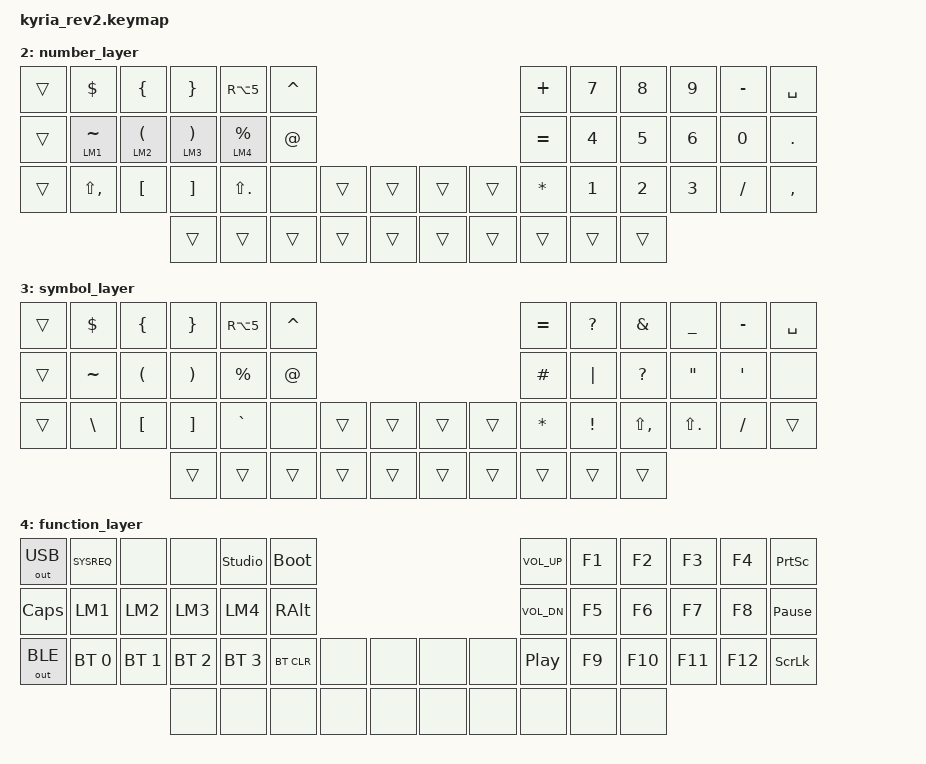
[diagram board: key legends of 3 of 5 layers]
/*
 * Copyright (c) 2020 The ZMK Contributors
 *
 * SPDX-License-Identifier: MIT
 */

#include <behaviors.dtsi>
#include <dt-bindings/zmk/keys.h>
#include <dt-bindings/zmk/bt.h>
#include <dt-bindings/zmk/outputs.h>

#include "lib/keys_os_colemak.h"
#include "lib/base.h"

//	---------------------------------------------------------------------------------------------------------------------------------
//	| 0   | 1   | 2   | 3   | 4   | 5   |                             | 6   | 7   | 8   | 9   | 10  | 11  |
//	| 12  | 13  | 14  | 15  | 16  | 17  |                             | 18  | 19  | 20  | 21  | 22  | 23  |
//	| 24  | 25  | 26  | 27  | 28  | 29  | 30  | 31  |     | 32  | 33  | 34  | 35  | 36  | 37  | 38  | 39  |
//	                  | 40  | 41  | 42  | 43  | 44  |     | 45  | 46  | 47  | 48  | 49  
#define KEYS_L 0 1 2 3 4 5    12 13 14 15 16 17  24 25 26 27 28 29
#define KEYS_R 6 7 8 9 10 11  18 19 20 21 22 23  34 35 36 37 38 39
#define KEYS_T 30 31  32 33   40 41 42 43 44     45 46 47 48 49

#define DEF 0
#define NAV 1
#define NUM 2
#define SYM 3
#define FUN 4
//#define ONE 5
//#define ON2 6

#define X_UNDO LC(Z)
#define X_REDO LC(LS(Z))
#define X_PASTE LC(V)
#define X_COPY LC(C)
#define X_CUT LC(X)

//#define COMBO_ALL(NAME, BINDINGS, KEYPOS) \
//  combo_##NAME { \
//    timeout-ms = <15>; \
//    bindings = <BINDINGS>; \
//    key-positions = <KEYPOS>; \
//  }
//
//#define COMBO_LAYER0(NAME, BINDINGS, KEYPOS) \
//  combo_##NAME { \
//    timeout-ms = <15>; \
//    bindings = <BINDINGS>; \
//    key-positions = <KEYPOS>; \
//    layers = <0>; \
//  }

/ {
	//behaviors {
	//	dk: double-key {
	//		compatible = "zmk,behavior-hold-tap";
	//		label = "DOUBLE_KEY";
	//		#binding-cells = <2>;
	//		flavor = "tap-preferred";
	//		tapping-term-ms = <200>;
	//		quick-tap-ms = <100>;
	//		#global-quick-tap;
	//		bindings = <&kp>, <&kp>;
	//	};
	//	hm: homerow_mods {
	//		compatible = "zmk,behavior-hold-tap";
	//		label = "HOMEROW_MODS";
	//		#binding-cells = <2>;
	//		flavor = "tap-preferred";
	//		tapping-term-ms = <150>;
	//		quick_tap_ms = <150>;
	//		bindings = <&kp>, <&kp>;
	//	};
	//	lm: left_hand_positional_hold_tap {
	//		compatible = "zmk,behavior-hold-tap";
	//		label = "LEFT_HOMEROW_MODS";
	//		#binding-cells = <2>;
	//		flavor = "tap-unless-interrupted";
	//		tapping-term-ms = <100>;
	//		quick-tap-ms = <200>;
	//		bindings = <&kp>, <&kp>;
	//		hold-trigger-key-positions = <6 7 8 9 10 11  18 19 20 21 22 23  34 35 36 37 38 39>;
	//	};
	//	rm: right_hand_positional_hold_tap {
	//		compatible = "zmk,behavior-hold-tap";
	//		label = "RIGHT_HOMEROW_MODS";
	//		#binding-cells = <2>;
	//		flavor = "tap-unless-interrupted";
	//		tapping-term-ms = <100>;
	//		quick-tap-ms = <200>;
	//		bindings = <&kp>, <&kp>;
	//		hold-trigger-key-positions = <0 1 2 3 4 5  12 13 14 15 16 17  24 25 26 27 28 29>;
	//	};
	//};

	macros {
		#include "lib/macros.dtsi"
	};

	behaviors {
		#include "lib/behaviors.dtsi"
	};

//	---------------------------------------------------------------------------------------------------------------------------------
//	| 0   | 1   | 2   | 3   | 4   | 5   |                             | 6   | 7   | 8   | 9   | 10  | 11  |
//	| 12  | 13  | 14  | 15  | 16  | 17  |                             | 18  | 19  | 20  | 21  | 22  | 23  |
//	| 24  | 25  | 26  | 27  | 28  | 29  | 30  | 31  |     | 32  | 33  | 34  | 35  | 36  | 37  | 38  | 39  |
//	                  | 40  | 41  | 42  | 43  | 44  |     | 45  | 46  | 47  | 48  | 49  

//	combos {
//		compatible = "zmk,combos";
//
//		COMBO_ALL(esc, &kp ESC, 1 2);
//		COMBO_ALL(tab, &kp TAB, 9 10);
//		COMBO_ALL(enter, &kp ENTER, 37 38);
//		COMBO_ALL(bspc, &kp BSPC, 13 14);
//
//		COMBO_ALL(l_ctrl_tab, &kp LC(TAB), 44 0);
//		COMBO_ALL(l_ctrl_shift_tab, &kp LC(LC(TAB)), 44 12);
//
//		COMBO_ALL(l_one, &tog ONE, 43 44);
//
//		//COMBO_LAYER0(lctrl, &sk LCTRL, 27 28);
//		COMBO_LAYER0(lalt, &sk LALT, 26 28);
//		COMBO_LAYER0(lgui, &sk LGUI, 25 28);
//		//COMBO_LAYER0(rctrl, &sk RCTRL, 35 36);
//		COMBO_LAYER0(rlalt, &sk LALT, 35 37);
//		COMBO_LAYER0(rgui, &sk RGUI, 35 38);
//
//		COMBO_LAYER0(caps_word_l, &caps_word, 27 28);
//		COMBO_LAYER0(caps_word_r, &caps_word, 37 38);
//	};

	//conditional_layers {
	//	compatible = "zmk,conditional-layers";
	//	tri_layer {
	//		if-layers = <SYM NUM>;
	//		then-layer = <FUN>;
	//	};
	//};

	keymap {
		compatible = "zmk,keymap";

		//  Colemak on OS side
		default_layer {
			//	---------------------------------------------------------------------------------------------------------------------------------
			//	| ??? | Q   | W   | E   | R   | T   |                             | Y   | U   | I   | O   | P   | ??? |
			//	| ??? | A   | S   | D   | F   | G   |                             | H   | J   | K   | L   | ;   | '   |
			//	| ??? | Z   | X   | C   | V   | B   | ??? | ??? |     | ??? | ??? | N   | M   | ,   | .   | /   | ??? |
			//	                  | ??? | ??? | ??? | ??? | ??? |     | ??? | ??? | ??? | ??? | ??? |
			bindings = <
&kp TAB       &kp OC_Q     &kp OC_W     &kp OC_F      &kp OC_P     &kp OC_G                            ___                 &kp OC_J      &kp OC_L     &kp OC_U     &kp OC_Y     &kp OC_AU    &kp OC_OU
&kp BSPC      &ml LM1 OC_A &ml LM2 OC_R &ml LM3 OC_S  &ml LM4 OC_T &ml RALT OC_D                       ___                 &mr RALT OC_H &mr RM1 OC_N &mr RM2 OC_E &mr RM3 OC_I &mr RM4 OC_O &kp SQT
&mt LSHFT ESC &kp OC_Z     &kp OC_X     &kp OC_C      &kp OC_V     &kp OC_B      &none         &none   ___ &none   &none   &kp OC_K      &kp OC_M     &kp COMMA    &kp DOT      &lt NAV FSLH &mt RSHFT RET
                                        &none         &kp RET      &mo FUN       &lt NAV SPACE &mo SYM ___ &mo NAV &mo SYM &mo FUN       &kp SPACE    &none
			>;
		};

		navigation_layer {
			bindings = <
&trans  &kp FSLH  &kp SPACE &kp HASH  &kp SPACE &kp F4                     ___               &kp INS   &kp PG_UP  &kp UP    &kp PG_DN &kp INS   &kp ESC
&trans  &kp LM1   &kp LM2   &kp LM3   &kp LM4   &ml RALT DEL               ___               &kp BSPC  &kp LEFT   &kp DOWN  &kp RIGHT &kp SPACE &kp DEL
&trans  &kp LC(Z) &kp LC(X) &kp LC(C) &kp LC(V) &kp X_PASTE  &none  &none  ___ &none  &none  &none     &kp HOME      &none      &kp END    &kp FSLH  &trans
                            &trans    &trans    &trans       &trans &trans ___ &trans &trans &trans    &trans     &trans
			>;
		};

		number_layer {
			//	---------------------------------------------------------------------------------------------------------------------------------
			//	|     | $   | {   | }   | €   | ^   |                             | -   | 7   | 8   | 9   | +   | /s  |
			//	|     | ~ X | ( X | ) X | % X | @   |                             | =   | 4   | 5   | 6   | 0   | .   |
			//	|     | <   | [   | ]   | >   |     | --- | --- |     | --- | --- | *   | 1   | 2   | 3   | /   | ,   |
			//	                  | --- | --- | --- | --- | --- |     | --- | --- | --- | --- | --- |
			bindings = <
&trans  &kp DLLR       &kp LBRC      &kp RBRC      &kp RA(N5)    &kp CARET                                &kp PLUS  &kp N7  &kp N8  &kp N9  &kp MINUS &kp SPACE
&trans  &mt LM1 TILDE  &mt LM2 LPAR  &mt LM3 RPAR  &mt LM4 PRCNT &kp AT                                   &kp EQUAL &kp N4  &kp N5  &kp N6  &kp N0    &kp DOT
&trans  &kp LS(COMMA)  &kp LBKT      &kp RBKT      &kp LS(DOT)   &none      &trans &trans   &trans &trans &kp STAR  &kp N1  &kp N2  &kp N3  &kp FSLH  &kp COMMA
   									 &trans        &trans        &trans     &trans &trans   &trans &trans &trans    &trans  &trans
			>;
		};

		symbol_layer {
			//	---------------------------------------------------------------------------------------------------------------------------------
			//	|     | $   | {   | }   | €   | ^   |                             | =   | ?   | &   | _   | -   |     |
			//	|     | ~   | (   | )   | %   | @   |                             | *   | |   | '   | "   | '   |     |
			//	|     | \   | [   | ]   | `   |     | --- | --- |     | --- | --- | #   | !   | <   | >   | /   |     |
			//	                  | --- | --- | --- | --- | --- |     | --- | --- | --- | --- | --- |
			bindings = <
&trans  &kp DLLR  &kp LBRC  &kp RBRC  &kp RA(N5) &kp CARET                                &kp EQUAL &kp QMARK &kp AMPS      &kp UNDER   &kp MINUS &kp SPACE
&trans  &kp TILDE &kp LPAR  &kp RPAR  &kp PRCNT  &kp AT                                   &kp HASH  &kp PIPE  &kp QMARK     &kp DQT     &kp SQT   &none
&trans  &kp BSLH  &kp LBKT  &kp RBKT  &kp GRAVE  &none      &trans &trans   &trans &trans &kp STAR  &kp EXCL  &kp LS(COMMA) &kp LS(DOT) &kp FSLH  &trans
                            &trans    &trans     &trans     &trans &trans   &trans &trans &trans    &trans    &trans
			>;
		};

		function_layer {
			bindings = <
&out OUT_USB &kp SYSREQ   &none        &none        &studio_unlock &bootloader                           &kp C_VOL_UP     &kp F1  &kp F2  &kp F3  &kp F4  &kp PRINTSCREEN
&kp CAPSLOCK &kp LM1      &kp LM2      &kp LM3      &kp LM4        &kp RALT                              &kp C_VOL_DN     &kp F5  &kp F6  &kp F7  &kp F8  &kp PAUSE_BREAK
&out OUT_BLE &bt BT_SEL 0 &bt BT_SEL 1 &bt BT_SEL 2 &bt BT_SEL 3   &bt BT_CLR  &none &none   &none &none &kp C_PLAY_PAUSE &kp F9  &kp F10 &kp F11 &kp F12 &kp SCROLLLOCK
                                       &none        &none          &none       &none &none   &none &none &none            &none   &none
			>;
		};

//		onehand_layer {
//			//	---------------------------------------------------------------------------------------------------------------------------------
//			//	| ??? | Q   | W   | E   | R   | T   |                             | Y   | U   | I   | O   | P   | ??? |
//			//	| ??? | A   | S   | D   | F   | G   |                             | H   | J   | K   | L   | ;   | ??? |
//			//	| ??? | Z   | X   | C   | V   | B   | ??? | ??? |     | ??? | ??? | N   | M   | ,   | .   | /   | ??? |
//			//	                  | ??? | ??? | ??? | ??? | ??? |     | ??? | ??? | ??? | ??? | ??? |
//			bindings = <
//	&kp ESC     &dk Q RA(Q) &dk W O   &dk E I     &dk R U  &dk T Y                                                 &dk Y T  &dk U R  &dk I E     &dk O W   &dk P Q    &kp RA(P)
//	&kp BSPC    &dk A RA(P) &dk S L   &dk D L     &dk F J  &dk G H                                                 &dk H G  &dk J F  &dk K D     &dk L S   &dk SEMI A &kp RA(Q)
//	&kp LSHFT   &dk Z FSLH  &dk X DOT &dk C COMMA &dk V M  &dk B N  &none         &none     &none        &none         &dk N B  &dk M V  &dk COMMA C &dk DOT X &dk FSLH Z &kp RSHIFT
//	                                  &to DEF     &to DEF  &mo SYM  &lt ON2 SPACE &kp RET   &mt LALT RET &lt SYM SPACE &mo NUM  &to DEF  &to DEF
//			>;
//		};

//		onehand_layer {
//			//	---------------------------------------------------------------------------------------------------------------------------------
//			//	| ??? | Q   | W   | E   | R   | T   |                             | Y   | U   | I   | O   | P   | ??? |
//			//	| ??? | A   | S   | D   | F   | G   |                             | H   | J   | K   | L   | ;   | ??? |
//			//	| ??? | Z   | X   | C   | V   | B   | ??? | ??? |     | ??? | ??? | N   | M   | ,   | .   | /   | ??? |
//			//	                  | ??? | ??? | ??? | ??? | ??? |     | ??? | ??? | ??? | ??? | ??? |
//			bindings = <
//	&kp ESC   &kp Q  &kp W  &kp E   &kp R   &kp T                                                         &kp Y   &kp U   &kp I     &kp O   &kp P    &kp RA(P)
//	&kp BSPC  &kp A  &kp S  &kp D   &kp F   &kp G                                                         &kp H   &kp J   &kp K     &kp L   &kp SEMI &kp RA(Q)
//	&kp LSHFT &kp Z  &kp X  &kp C   &kp V   &kp B   &none         &none         &none       &none         &kp N   &kp M   &kp COMMA &kp DOT &kp FSLH &kp RSHIFT
//	                        &to DEF &to DEF &mo SYM &lt ON2 SPACE &lt NUM RET   &lt NUM RET &lt ON2 SPACE &mo NUM &to DEF &to DEF
//			>;
//		};
//
//		onehand_layer_2 {
//			bindings = <
//	&kp RA(P) &kp P    &kp O   &kp I     &kp U  &kp Y                                &kp T  &kp R  &kp E  &kp W  &kp Q  &kp ESC
//	&kp RA(Q) &kp SEMI &kp L   &kp K     &kp J  &kp H                                &kp G  &kp F  &kp D  &kp S  &kp A  &kp BSPC
//	&kp LSHFT &kp FSLH &kp DOT &kp COMMA &kp M  &kp N  &none  &none    &none  &none  &kp B  &kp V  &kp C  &kp X  &kp Z  &kp RSHIFT
//	                           &trans    &trans &trans &trans &trans   &trans &trans &trans &trans &trans
//			>;
//		};
	};
};
